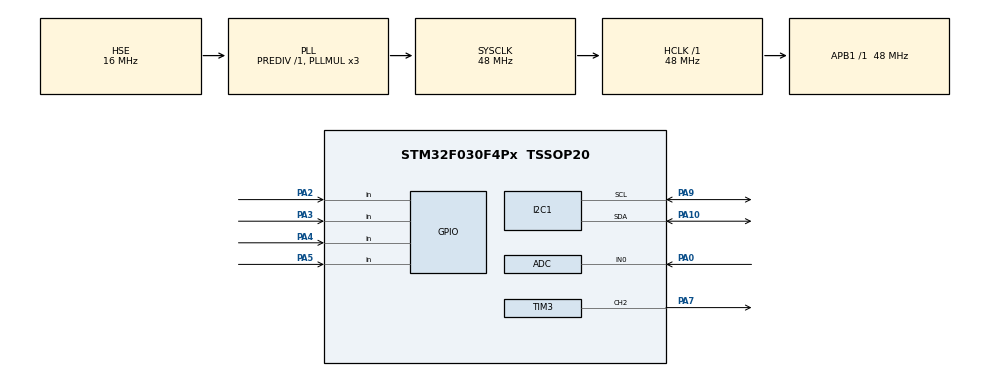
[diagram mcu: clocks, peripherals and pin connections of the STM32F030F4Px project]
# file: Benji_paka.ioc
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ADC.SamplingTime=ADC_SAMPLETIME_55CYCLES_5
Mcu.Family=STM32F0
Mcu.Name=STM32F030F4Px
Mcu.Package=TSSOP20
NVIC.TIM1_BRK_UP_TRG_COM_IRQn=true\:0\:0\:false\:false\:true\:true\:true
PA0.Mode=IN0
PA0.Signal=ADC_IN0
PA10.Mode=I2C
PA10.Signal=I2C1_SDA
PA13.Mode=Serial_Wire
PA13.Signal=SYS_SWDIO
PA14.Mode=Serial_Wire
PA14.Signal=SYS_SWCLK
PA2.GPIO_PuPd=GPIO_NOPULL
PA2.Signal=GPIO_Input
PA3.Signal=GPIO_Input
PA4.Signal=GPIO_Input
PA5.Signal=GPIO_Input
PA7.Signal=S_TIM3_CH2
PA9.Mode=I2C
PA9.Signal=I2C1_SCL
PF0-OSC_IN.Mode=HSE-External-Oscillator
PF0-OSC_IN.Signal=RCC_OSC_IN
PF1-OSC_OUT.Mode=HSE-External-Oscillator
PF1-OSC_OUT.Signal=RCC_OSC_OUT
ProjectManager.HeapSize=0x300
ProjectManager.StackSize=0x500
ProjectManager.TargetToolchain=MDK-ARM V5.27
RCC.AHBFreq_Value=48000000
RCC.APB1Freq_Value=48000000
RCC.APB1TimFreq_Value=48000000
RCC.HCLKFreq_Value=48000000
RCC.HSE_VALUE=16000000
RCC.PLLMUL=RCC_PLL_MUL3
RCC.PLLSourceVirtual=RCC_PLLSOURCE_HSE
RCC.SYSCLKFreq_VALUE=48000000
RCC.SYSCLKSource=RCC_SYSCLKSOURCE_PLLCLK
SH.S_TIM3_CH2.0=TIM3_CH2,PWM Generation2 CH2
TIM1.Period=100
TIM1.Prescaler=4800
TIM3.Channel-PWM\ Generation2\ CH2=TIM_CHANNEL_2
TIM3.Period=100
TIM3.Prescaler=480
VP_TIM1_VS_ClockSourceINT.Mode=Internal
board=custom

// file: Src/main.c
/* USER CODE BEGIN Header */
/**
  ******************************************************************************
  * @file           : main.c
  * @brief          : Main program body
  ******************************************************************************
  * @attention
  *
  * <h2><center>&copy; Copyright (c) 2020 STMicroelectronics.
  * All rights reserved.</center></h2>
  *
  * This software component is licensed by ST under BSD 3-Clause license,
  * the "License"; You may not use this file except in compliance with the
  * License. You may obtain a copy of the License at:
  *                        opensource.org/licenses/BSD-3-Clause
  *
  ******************************************************************************
  */
/* USER CODE END Header */

#include "main.h"

/* USER CODE BEGIN Includes */
#include "ssd1306.h"
#include <stdio.h>
#include "arm_math.h"
/* USER CODE END Includes */

/* USER CODE BEGIN PD */
#define PID_PARAM_KP        700          /* Proportional */
#define PID_PARAM_KI        13         /* Integral */
#define PID_PARAM_KD        0            /* Derivative */
/* USER CODE END PD */

ADC_HandleTypeDef hadc;

I2C_HandleTypeDef hi2c1;

TIM_HandleTypeDef htim1;
TIM_HandleTypeDef htim3;

void SystemClock_Config(void);
static void MX_GPIO_Init(void);
static void MX_ADC_Init(void);
static void MX_I2C1_Init(void);
static void MX_TIM1_Init(void);
static void MX_TIM3_Init(void);
/* USER CODE BEGIN PFP */
void setPWM(TIM_HandleTypeDef timer, uint32_t channel, uint16_t period,
uint16_t pulse);
/* USER CODE END PFP */

/* USER CODE BEGIN 0 */
uint8_t presetcount = 2;
uint8_t lastbutton1;
uint8_t lastbutton2;
uint8_t lastbutton3;
uint8_t actbutton1;
uint8_t actbutton2;
uint8_t actbutton3;
uint8_t prelltimer;
unsigned int setpoint = 260;
unsigned int millis;
unsigned int adctime;
unsigned int adcbuffer[10];
char buffer[50];
unsigned int adcpointer;
unsigned int rollingavarage;
unsigned int voltage;
int preverror;
int piderror;
int interror;
int output;
int pwmvalue;
int pidtime;
/* USER CODE END 0 */

int main(void)
{

  /* MCU Configuration--------------------------------------------------------*/

  /* Reset of all peripherals, Initializes the Flash interface and the Systick. */
  HAL_Init();

  /* Configure the system clock */
  SystemClock_Config();

  /* USER CODE BEGIN SysInit */
	  arm_pid_instance_f32 PID;
		PID.Kp = PID_PARAM_KP;        /* Proporcional */
    PID.Ki = PID_PARAM_KI;        /* Integral */
    PID.Kd = PID_PARAM_KD;        /* Derivative */
	  arm_pid_init_f32(&PID, 1);
  /* USER CODE END SysInit */

  /* Initialize all configured peripherals */
  MX_GPIO_Init();
  MX_ADC_Init();
  MX_I2C1_Init();
  MX_TIM1_Init();
  MX_TIM3_Init();
  /* USER CODE BEGIN 2 */
	HAL_TIM_Base_Start_IT(&htim1);
	HAL_TIM_PWM_Start(&htim3,TIM_CHANNEL_1);

  /* USER CODE END 2 */

  /* Infinite loop */
  /* USER CODE BEGIN WHILE */

  while (1)
  {
		HAL_GPIO_TogglePin(GPIOA,GPIO_PIN_6);
		actbutton1 = HAL_GPIO_ReadPin(GPIOA,GPIO_PIN_4);
	  actbutton2 = HAL_GPIO_ReadPin(GPIOA,GPIO_PIN_3);
		actbutton3 = HAL_GPIO_ReadPin(GPIOA,GPIO_PIN_5);
		if((actbutton1 != lastbutton1)||(actbutton2 != lastbutton2)||(actbutton3 != lastbutton3))
		{
			prelltimer = 5;
			while(prelltimer >0)
			{
				actbutton1 = HAL_GPIO_ReadPin(GPIOA,GPIO_PIN_4);
				actbutton2 = HAL_GPIO_ReadPin(GPIOA,GPIO_PIN_3);
				actbutton3 = HAL_GPIO_ReadPin(GPIOA,GPIO_PIN_5);
					if(	actbutton1 != lastbutton1)
					{
						prelltimer = 5;
					}
					lastbutton1 = actbutton1;
					if(	actbutton2 != lastbutton2)
					{
						prelltimer = 5;
					}
					lastbutton2 = actbutton2;
					if(	actbutton3 != lastbutton3)
					{
						prelltimer = 5;
					}
					lastbutton3 = actbutton3;
			}
			if(actbutton1 == 0)
					{
						setpoint = setpoint + 5;
					}
			if(actbutton2 == 0)
			{
				setpoint = setpoint - 5;
			}
			if(actbutton3 == 0)
			{
				presetcount++;
				if(presetcount >5)
				{
					presetcount = 1;
			}
			if(setpoint > 450)
			{
				setpoint = 450;
			}
			if(setpoint < 50)
			{
				setpoint = 50;
			}
			switch(presetcount)
			{
				case 1:
					setpoint = 280;
					break;
				case 2:
					setpoint = 300;
					break;
				case 3:
					setpoint = 320;
					break;
				case 4:
					setpoint = 360;
					break;
				case 5:
					setpoint = 400;
					break;
			}
		}
	}

if(pidtime > 300)
{
	if((voltage - setpoint) > 10)
	{
		arm_pid_init_f32(&PID, 1);
	}
	piderror = setpoint - voltage;
			pwmvalue = arm_pid_f32(&PID,piderror);
			if(pwmvalue >10000)
			{
				pwmvalue = 10000;
			}else if(pwmvalue <0)
			{
				pwmvalue = 0;
			}
			setPWM(htim3,TIM_CHANNEL_2,10000,pwmvalue);
	pidtime = 0;
}

		if(millis >50)
		{
			for(int i = 0;i<10;i++)
			{
				rollingavarage += adcbuffer[i];
			}
			rollingavarage = rollingavarage/11;
			voltage = (int)(rollingavarage*3300)/4096;
      voltage = voltage/3.99;
			piderror = voltage-setpoint ;

			ssd1306_SetCursor(0,0);
			sprintf(buffer,"SET: %d   ",setpoint);
			ssd1306_WriteString(buffer,Font_11x18,White);
			ssd1306_SetCursor(0,19);
			sprintf(buffer,"ACT: %d   ",voltage);
			ssd1306_WriteString(buffer,Font_11x18,White);
			ssd1306_SetCursor(0,40);
			sprintf(buffer,"DC: %d%c   ",(int)(pwmvalue/100),37);
			ssd1306_WriteString(buffer,Font_11x18,White);

			ssd1306_UpdateScreen();
			millis = 0;
		}

    /* USER CODE END WHILE */

  }
}

void SystemClock_Config(void)
{
  RCC_OscInitTypeDef RCC_OscInitStruct = {0};
  RCC_ClkInitTypeDef RCC_ClkInitStruct = {0};
  RCC_PeriphCLKInitTypeDef PeriphClkInit = {0};

  /** Initializes the CPU, AHB and APB busses clocks
  */
  RCC_OscInitStruct.OscillatorType = RCC_OSCILLATORTYPE_HSI|RCC_OSCILLATORTYPE_HSI14
                              |RCC_OSCILLATORTYPE_HSE;
  RCC_OscInitStruct.HSEState = RCC_HSE_ON;
  RCC_OscInitStruct.HSIState = RCC_HSI_ON;
  RCC_OscInitStruct.HSI14State = RCC_HSI14_ON;
  RCC_OscInitStruct.HSICalibrationValue = RCC_HSICALIBRATION_DEFAULT;
  RCC_OscInitStruct.HSI14CalibrationValue = 16;
  RCC_OscInitStruct.PLL.PLLState = RCC_PLL_ON;
  RCC_OscInitStruct.PLL.PLLSource = RCC_PLLSOURCE_HSE;
  RCC_OscInitStruct.PLL.PLLMUL = RCC_PLL_MUL3;
  RCC_OscInitStruct.PLL.PREDIV = RCC_PREDIV_DIV1;
  if (HAL_RCC_OscConfig(&RCC_OscInitStruct) != HAL_OK)
  {
    Error_Handler();
  }
  /** Initializes the CPU, AHB and APB busses clocks
  */
  RCC_ClkInitStruct.ClockType = RCC_CLOCKTYPE_HCLK|RCC_CLOCKTYPE_SYSCLK
                              |RCC_CLOCKTYPE_PCLK1;
  RCC_ClkInitStruct.SYSCLKSource = RCC_SYSCLKSOURCE_PLLCLK;
  RCC_ClkInitStruct.AHBCLKDivider = RCC_SYSCLK_DIV1;
  RCC_ClkInitStruct.APB1CLKDivider = RCC_HCLK_DIV1;

  if (HAL_RCC_ClockConfig(&RCC_ClkInitStruct, FLASH_LATENCY_1) != HAL_OK)
  {
    Error_Handler();
  }
  PeriphClkInit.PeriphClockSelection = RCC_PERIPHCLK_I2C1;
  PeriphClkInit.I2c1ClockSelection = RCC_I2C1CLKSOURCE_HSI;
  if (HAL_RCCEx_PeriphCLKConfig(&PeriphClkInit) != HAL_OK)
  {
    Error_Handler();
  }
}

static void MX_ADC_Init(void)
{

  ADC_ChannelConfTypeDef sConfig = {0};

  /** Configure the global features of the ADC (Clock, Resolution, Data Alignment and number of conversion)
  */
  hadc.Instance = ADC1;
  hadc.Init.ClockPrescaler = ADC_CLOCK_ASYNC_DIV1;
  hadc.Init.Resolution = ADC_RESOLUTION_12B;
  hadc.Init.DataAlign = ADC_DATAALIGN_RIGHT;
  hadc.Init.ScanConvMode = ADC_SCAN_DIRECTION_FORWARD;
  hadc.Init.EOCSelection = ADC_EOC_SINGLE_CONV;
  hadc.Init.LowPowerAutoWait = DISABLE;
  hadc.Init.LowPowerAutoPowerOff = DISABLE;
  hadc.Init.ContinuousConvMode = DISABLE;
  hadc.Init.DiscontinuousConvMode = DISABLE;
  hadc.Init.ExternalTrigConv = ADC_SOFTWARE_START;
  hadc.Init.ExternalTrigConvEdge = ADC_EXTERNALTRIGCONVEDGE_NONE;
  hadc.Init.DMAContinuousRequests = DISABLE;
  hadc.Init.Overrun = ADC_OVR_DATA_PRESERVED;
  if (HAL_ADC_Init(&hadc) != HAL_OK)
  {
    Error_Handler();
  }
  /** Configure for the selected ADC regular channel to be converted.
  */
  sConfig.Channel = ADC_CHANNEL_0;
  sConfig.Rank = ADC_RANK_CHANNEL_NUMBER;
  sConfig.SamplingTime = ADC_SAMPLETIME_239CYCLES_5;
  if (HAL_ADC_ConfigChannel(&hadc, &sConfig) != HAL_OK)
  {
    Error_Handler();
  }

}

static void MX_I2C1_Init(void)
{

  hi2c1.Instance = I2C1;
  hi2c1.Init.Timing = 0x2000090E;
  hi2c1.Init.OwnAddress1 = 0;
  hi2c1.Init.AddressingMode = I2C_ADDRESSINGMODE_7BIT;
  hi2c1.Init.DualAddressMode = I2C_DUALADDRESS_DISABLE;
  hi2c1.Init.OwnAddress2 = 0;
  hi2c1.Init.OwnAddress2Masks = I2C_OA2_NOMASK;
  hi2c1.Init.GeneralCallMode = I2C_GENERALCALL_DISABLE;
  hi2c1.Init.NoStretchMode = I2C_NOSTRETCH_DISABLE;
  if (HAL_I2C_Init(&hi2c1) != HAL_OK)
  {
    Error_Handler();
  }
  /** Configure Analogue filter
  */
  if (HAL_I2CEx_ConfigAnalogFilter(&hi2c1, I2C_ANALOGFILTER_ENABLE) != HAL_OK)
  {
    Error_Handler();
  }
  /** Configure Digital filter
  */
  if (HAL_I2CEx_ConfigDigitalFilter(&hi2c1, 0) != HAL_OK)
  {
    Error_Handler();
  }

}

static void MX_TIM1_Init(void)
{

  TIM_ClockConfigTypeDef sClockSourceConfig = {0};
  TIM_MasterConfigTypeDef sMasterConfig = {0};

  htim1.Instance = TIM1;
  htim1.Init.Prescaler = 480;
  htim1.Init.CounterMode = TIM_COUNTERMODE_UP;
  htim1.Init.Period = 100;
  htim1.Init.ClockDivision = TIM_CLOCKDIVISION_DIV1;
  htim1.Init.RepetitionCounter = 0;
  htim1.Init.AutoReloadPreload = TIM_AUTORELOAD_PRELOAD_DISABLE;
  if (HAL_TIM_Base_Init(&htim1) != HAL_OK)
  {
    Error_Handler();
  }
  sClockSourceConfig.ClockSource = TIM_CLOCKSOURCE_INTERNAL;
  if (HAL_TIM_ConfigClockSource(&htim1, &sClockSourceConfig) != HAL_OK)
  {
    Error_Handler();
  }
  sMasterConfig.MasterOutputTrigger = TIM_TRGO_RESET;
  sMasterConfig.MasterSlaveMode = TIM_MASTERSLAVEMODE_DISABLE;
  if (HAL_TIMEx_MasterConfigSynchronization(&htim1, &sMasterConfig) != HAL_OK)
  {
    Error_Handler();
  }

}

static void MX_TIM3_Init(void)
{

  TIM_MasterConfigTypeDef sMasterConfig = {0};
  TIM_OC_InitTypeDef sConfigOC = {0};

  htim3.Instance = TIM3;
  htim3.Init.Prescaler = 10;
  htim3.Init.CounterMode = TIM_COUNTERMODE_UP;
  htim3.Init.Period = 100;
  htim3.Init.ClockDivision = TIM_CLOCKDIVISION_DIV1;
  htim3.Init.AutoReloadPreload = TIM_AUTORELOAD_PRELOAD_DISABLE;
  if (HAL_TIM_PWM_Init(&htim3) != HAL_OK)
  {
    Error_Handler();
  }
  sMasterConfig.MasterOutputTrigger = TIM_TRGO_RESET;
  sMasterConfig.MasterSlaveMode = TIM_MASTERSLAVEMODE_DISABLE;
  if (HAL_TIMEx_MasterConfigSynchronization(&htim3, &sMasterConfig) != HAL_OK)
  {
    Error_Handler();
  }
  sConfigOC.OCMode = TIM_OCMODE_PWM1;
  sConfigOC.Pulse = 0;
  sConfigOC.OCPolarity = TIM_OCPOLARITY_HIGH;
  sConfigOC.OCFastMode = TIM_OCFAST_DISABLE;
  if (HAL_TIM_PWM_ConfigChannel(&htim3, &sConfigOC, TIM_CHANNEL_2) != HAL_OK)
  {
    Error_Handler();
  }
  HAL_TIM_MspPostInit(&htim3);

}

static void MX_GPIO_Init(void)
{
  GPIO_InitTypeDef GPIO_InitStruct = {0};

  /* GPIO Ports Clock Enable */
  __HAL_RCC_GPIOF_CLK_ENABLE();
  __HAL_RCC_GPIOA_CLK_ENABLE();

	GPIO_InitStruct.Pin = GPIO_PIN_6;
  GPIO_InitStruct.Mode = GPIO_MODE_OUTPUT_PP;
  GPIO_InitStruct.Pull = GPIO_NOPULL;
  GPIO_InitStruct.Speed = GPIO_SPEED_FREQ_MEDIUM;
  HAL_GPIO_Init(GPIOA, &GPIO_InitStruct);

  /*Configure GPIO pins : PA2 PA3 PA4 PA5 */
  GPIO_InitStruct.Pin = GPIO_PIN_2|GPIO_PIN_3|GPIO_PIN_4|GPIO_PIN_5;
  GPIO_InitStruct.Mode = GPIO_MODE_INPUT;
  GPIO_InitStruct.Pull = GPIO_NOPULL;
  HAL_GPIO_Init(GPIOA, &GPIO_InitStruct);

}

/* USER CODE BEGIN 4 */

void setPWM(TIM_HandleTypeDef timer, uint32_t channel, uint16_t period,
uint16_t pulse)
{
 HAL_TIM_PWM_Stop(&timer, channel); // stop generation of pwm
 TIM_OC_InitTypeDef sConfigOC;//struktúra
 timer.Init.Period = period; // set the period duration
 HAL_TIM_PWM_Init(&timer); // reinititialise with new period value
 sConfigOC.OCMode = TIM_OCMODE_PWM1;
 sConfigOC.Pulse = pulse; // set the pulse duration
 sConfigOC.OCPolarity = TIM_OCPOLARITY_HIGH;
 sConfigOC.OCFastMode = TIM_OCFAST_DISABLE;
 HAL_TIM_PWM_ConfigChannel(&timer, &sConfigOC, channel);
 HAL_TIM_PWM_Start(&timer, channel); // start pwm generation
}
void HAL_TIM_PeriodElapsedCallback(TIM_HandleTypeDef *htim)
{
	HAL_GPIO_TogglePin(GPIOA,GPIO_PIN_6);
	if(prelltimer >0)
	{
	prelltimer--;
	}
	millis++;
	pidtime++;
	adctime++;
	if(adctime >20)
		{

			HAL_ADC_Start(&hadc);
			HAL_ADC_PollForConversion(&hadc,100);
			adcbuffer[adcpointer] = HAL_ADC_GetValue(&hadc);
			HAL_ADC_Stop(&hadc);
			adcpointer++;
			if(adcpointer >=10)
			{
				adcpointer = 0;
			}
			adctime = 0;
		}

}
/* USER CODE END 4 */

void Error_Handler(void)
{
}

/************************ (C) COPYRIGHT STMicroelectronics *****END OF FILE****/
